# ESP32S31_RADIO register map
Vendor: Espressif; Series: ESP32-S31; File version: 3.52
Registers are 32-bit, read-write, no defined reset value unless marked. A register's access mark holds for its fields unless they carry their own. Offsets are from the block's base; [hi:lo] are bit positions; {n}, {i} and the like mark numbered series.

## BTMAC_BLE_PHY_INIT — ESP32-S31 BTMAC words initialized by the complete BLE PHY register-init function. The function identity is supported by the matching ble_phy.c object layout from the ESP32-C61 ecosystem library, while every address, mask and value below comes only from the ESP32-S31 artifact. Neutral INIT names retain the exact operation without promoting the cross-chip hint to hardware truth.
Base 0x20101400
0x74 INIT_ZERO_0074 — BLE PHY register initialization writes the complete zero image. Inner hardware semantics remain unknown.
  [31:0] INIT_IMAGE
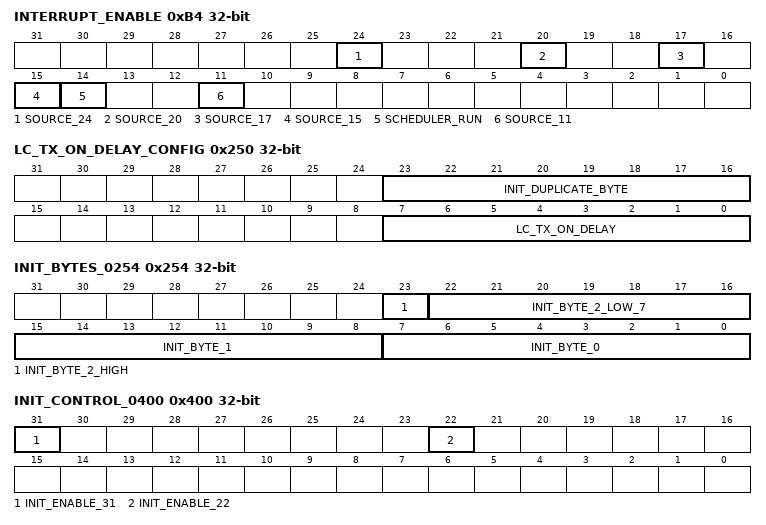
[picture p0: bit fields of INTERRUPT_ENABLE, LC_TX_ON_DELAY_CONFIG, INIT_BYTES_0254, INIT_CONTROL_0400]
0xB4 INTERRUPT_ENABLE — BLE base-stack interrupt enable bank. BLE PHY initialization preserves only source 17 and later enables sources 11, 15, 20 and 24. The synchronous scheduler-run subscriber clears stale source 14 before enabling it here. All omitted source identities remain unknown.
  [24] SOURCE_24 — The conditional BLE PHY initialization tail enables source 24. Its feature identity remains unknown.
  [20] SOURCE_20 — The conditional BLE PHY initialization tail enables source 20. Its feature identity remains unknown.
  [17] SOURCE_17 — BLE PHY initialization preserves source 17 while disabling every other interrupt source. Its feature identity remains unknown.
  [15] SOURCE_15 — The conditional BLE PHY initialization tail enables source 15. Its feature identity remains unknown.
  [14] SCHEDULER_RUN — The synchronous base-stack subscriber enables source 14 immediately before the scheduler RUN command.
  [11] SOURCE_11 — The conditional BLE PHY initialization tail enables source 11. Its feature identity remains unknown.
0xB8 INTERRUPT_CLEAR wo write-1-clears — Write-one-to-clear BLE base-stack interrupt bank. Initialization acknowledges every source with an all-ones image; the synchronous scheduler-run subscriber acknowledges source 14 before enabling it.
  [14] SCHEDULER_RUN — A one acknowledges stale scheduler-run source 14 before that source is enabled.
0xC4 INIT_CONTROL_00C4 — The conditional tail of complete BLE PHY register initialization sets bit 9 through a fresh-read RMW. All other bits are preserved and their meanings remain unknown.
  [9] INIT_ENABLE_9
0x138 INIT_VALUE_0138 — BLE PHY register initialization writes the finite complete image 0x0000065B.
  [31:0] INIT_IMAGE
0x250 LC_TX_ON_DELAY_CONFIG — BLE transmit timing configuration. ble_tx_config_check independently prints byte zero as lc_tx_on_delay; BLE PHY initialization writes the same runtime-derived byte image into bytes zero and two.
  [23:16] INIT_DUPLICATE_BYTE — BLE PHY initialization receives the same configuration-byte-minus-one image as LC_TX_ON_DELAY. No independent semantic name is claimed.
  [7:0] LC_TX_ON_DELAY — Low byte printed as lc_tx_on_delay by complete ble_tx_config_check. BLE PHY initialization stores a configuration byte minus one.
0x254 INIT_BYTES_0254 — BLE PHY initialization replaces the first three bytes with the exact images 0x01, 0x01 and 0xB2.
  [23] INIT_BYTE_2_HIGH — The first byte-two clear preserves this bit and the following OR forces it to one.
  [22:16] INIT_BYTE_2_LOW_7
  [15:8] INIT_BYTE_1
  [7:0] INIT_BYTE_0
0x400 INIT_CONTROL_0400 — BLE PHY initialization first writes bit 31 as a complete image and then sets bit 22 through a fresh-read RMW.
  [31] INIT_ENABLE_31, [22] INIT_ENABLE_22
0x458 INIT_HIGH_HALF_0458 — BLE PHY initialization replaces the upper halfword with the finite image 0x000F.
  [31:16] INIT_HIGH_HALF
0x45C INIT_VALUE_045C — BLE PHY register initialization writes the finite complete image 8.
  [31:0] INIT_IMAGE
0x470 INIT_BRANCH_CONTROL_0470 — One complete BLE PHY initialization branch sets bit 18 through a fresh-read RMW. The alternate branch leaves the word unchanged; every other bit and the branch condition's hardware meaning remain unknown.
  [18] SET_BY_PHY_INIT_BRANCH_BIT_18 — The complete BLE PHY initialization body's selected branch sets this positional bit. No independent enable, allowlist, or directed-advertising hardware meaning is proven.
0x4A0 INIT_DYNAMIC_IMAGE_04A0 — BLE PHY initialization writes a runtime-derived complete image formed from a linked global address. The destination's hardware meaning remains unknown.
  [31:0] INIT_IMAGE
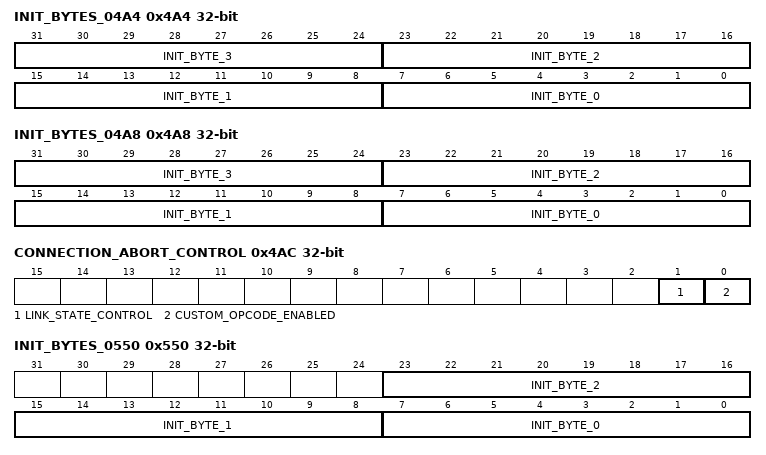
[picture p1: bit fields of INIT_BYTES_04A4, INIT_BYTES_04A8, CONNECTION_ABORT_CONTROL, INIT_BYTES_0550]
0x4A4 INIT_BYTES_04A4 — BLE PHY register initialization writes four byte images equal to 2.
  [8n+7:8n] INIT_BYTE_{n} (n=0..3)
0x4A8 INIT_BYTES_04A8 — BLE PHY register initialization writes four byte images equal to 2.
  [8n+7:8n] INIT_BYTE_{n} (n=0..3)
0x4AC CONNECTION_ABORT_CONTROL — Connection aborted-opcode control. BLE PHY initialization and the default aborted-opcode path write 0x00FF0002, while the custom-opcode path writes 0x00FF0003. Connection link-state refresh independently replaces bit 1 from its two private control flags.
  [1] LINK_STATE_CONTROL — The complete connection link-state refresh clears this bit only when both of its private control flags are set and sets it on every other path. The inner hardware meaning remains unresolved.
  [0] CUSTOM_OPCODE_ENABLED
0x540 INIT_VALUE_0540 — BLE PHY register initialization writes the finite complete image 2000.
  [31:0] INIT_IMAGE
0x54C INIT_LOW_5_054C — BLE PHY initialization replaces the low five bits with the finite image 0x12.
  [4:0] INIT_LOW_5
0x550 INIT_BYTES_0550 — BLE PHY initialization replaces the low three bytes with 0x03, 0x03 and 0x44.
  [23:16] INIT_BYTE_2, [15:8] INIT_BYTE_1, [7:0] INIT_BYTE_0
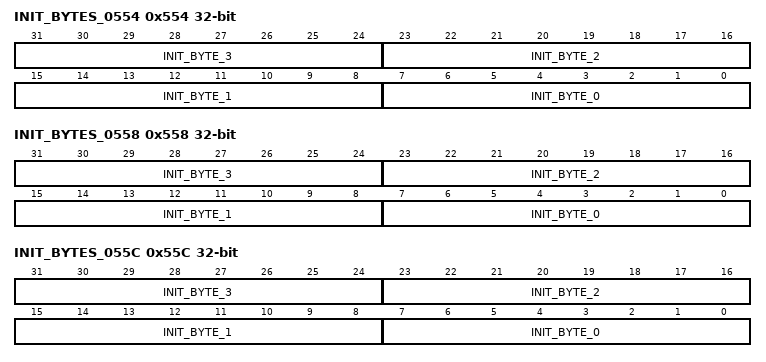
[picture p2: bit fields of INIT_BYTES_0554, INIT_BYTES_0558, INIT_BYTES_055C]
0x554 INIT_BYTES_0554 — BLE PHY initialization replaces all four bytes with 0x10, 0x10, 0x3C and 0x28.
  [8n+7:8n] INIT_BYTE_{n} (n=0..3)
0x558 INIT_BYTES_0558 — BLE PHY initialization replaces all four bytes with 0x0C, 0x08, 0x0C and 0x0C.
  [8n+7:8n] INIT_BYTE_{n} (n=0..3)
0x55C INIT_BYTES_055C — BLE PHY initialization replaces all four bytes with 0x08.
  [8n+7:8n] INIT_BYTE_{n} (n=0..3)
